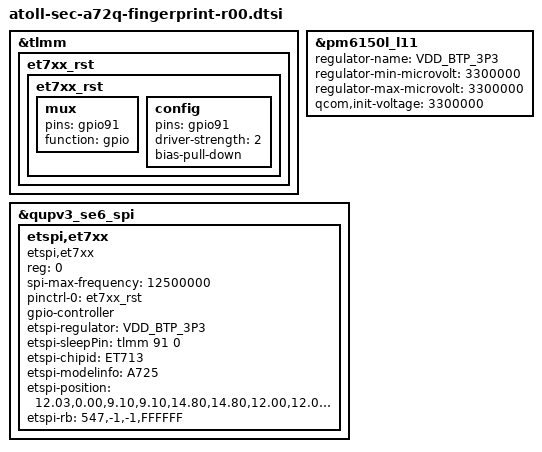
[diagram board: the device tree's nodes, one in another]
/* Copyright (c) 2013-2019, The Linux Foundation. All rights reserved.
 *
 * This program is free software; you can redistribute it and/or modify
 * it under the terms of the GNU General Public License version 2 and
 * only version 2 as published by the Free Software Foundation.
 *
 * This program is distributed in the hope that it will be useful,
 * but WITHOUT ANY WARRANTY; without even the implied warranty of
 * MERCHANTABILITY or FITNESS FOR A PARTICULAR PURPOSE.  See the
 * GNU General Public License for more details.
 */

&tlmm {
	et7xx_rst {
		et7xx_rst: et7xx_rst {
			mux {
				pins = "gpio91";
				function = "gpio";
			};
			config {
				pins = "gpio91";
				driver-strength = <2>;
				bias-pull-down;
			};
		};
	};
};

&pm6150l_l11 {
	regulator-name = "VDD_BTP_3P3";
	regulator-min-microvolt = <3300000>;
	regulator-max-microvolt = <3300000>;
	qcom,init-voltage = <3300000>;
};

&qupv3_se6_spi {
	status = "okay";

	etspi,et7xx {
		compatible = "etspi,et7xx";
		reg = <0>;
		spi-max-frequency = <12500000>;

		pinctrl-names = "default";
		pinctrl-0 = <&et7xx_rst>;

		gpio-controller;
		#gpio-cells = <2>;

		etspi-regulator = "VDD_BTP_3P3";
		etspi-sleepPin = <&tlmm 91 0>;
		etspi-chipid = "ET713";
		etspi-modelinfo = "A725";
		etspi-position = "12.03,0.00,9.10,9.10,14.80,14.80,12.00,12.00,5.00";
		etspi-rb = "547,-1,-1,FFFFFF";
	};
};
